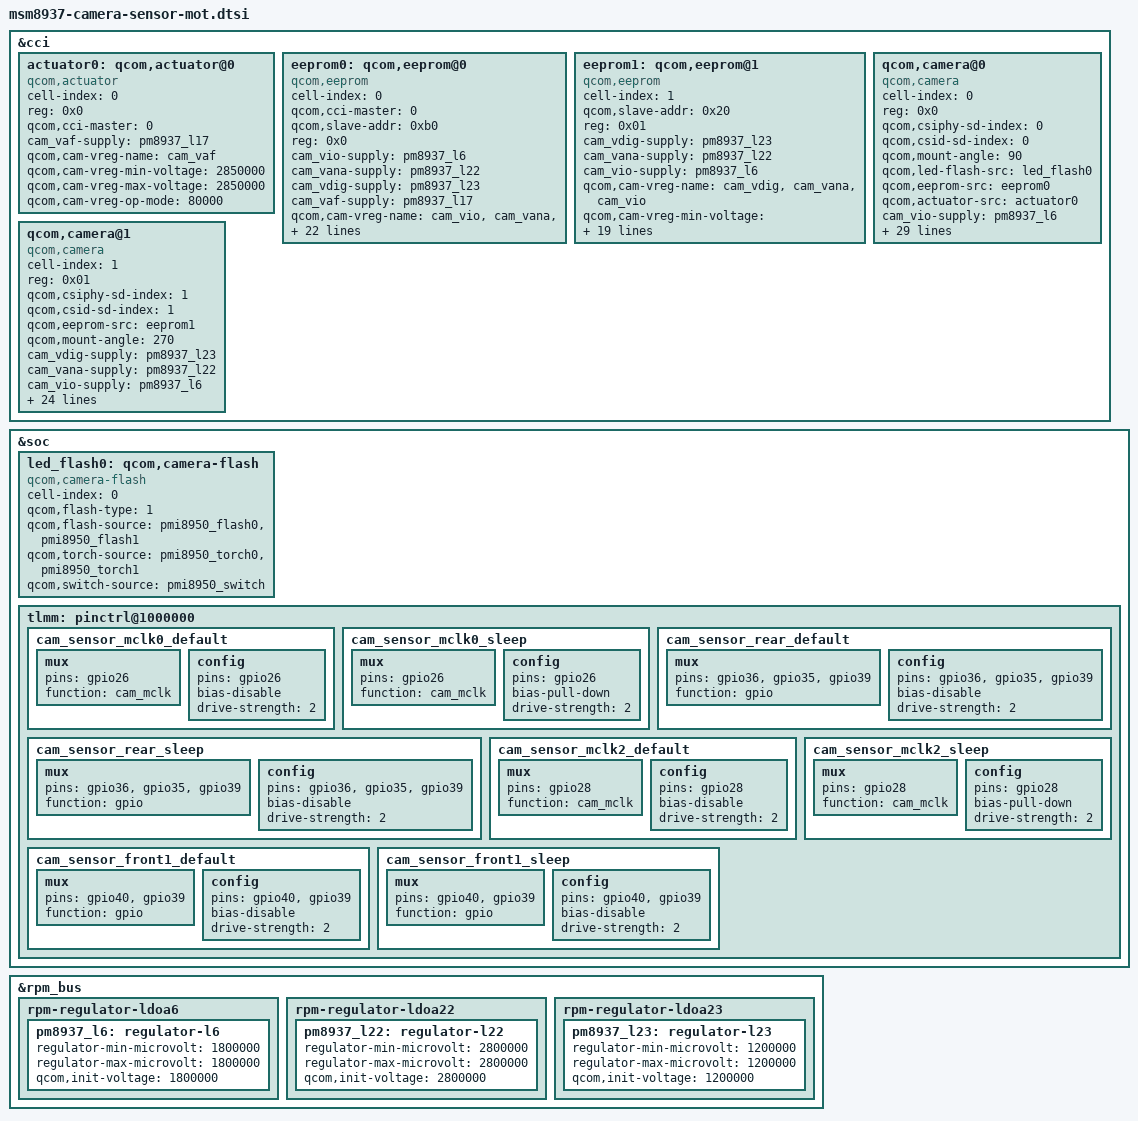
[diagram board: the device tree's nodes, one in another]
/*
 * Copyright (c) 2015-2016, The Linux Foundation. All rights reserved.
 *
 * This program is free software; you can redistribute it and/or modify
 * it under the terms of the GNU General Public License version 2 and
 * only version 2 as published by the Free Software Foundation.
 *
 * This program is distributed in the hope that it will be useful,
 * but WITHOUT ANY WARRANTY; without even the implied warranty of
 * MERCHANTABILITY or FITNESS FOR A PARTICULAR PURPOSE.  See the
 * GNU General Public License for more details.
 */

&cci {
	actuator0: qcom,actuator@0 {
		cell-index = <0>;
		reg = <0x0>;
		compatible = "qcom,actuator";
		qcom,cci-master = <0>;
		cam_vaf-supply = <&pm8937_l17>;
		qcom,cam-vreg-name = "cam_vaf";
		qcom,cam-vreg-min-voltage = <2850000>;
		qcom,cam-vreg-max-voltage = <2850000>;
		qcom,cam-vreg-op-mode = <80000>;
	};

	eeprom0: qcom,eeprom@0 {
		cell-index = <0>;
		compatible = "qcom,eeprom";
		qcom,cci-master = <0>;
		qcom,slave-addr = <0xb0>;
		reg = <0x0>;
		cam_vio-supply = <&pm8937_l6>;
		cam_vana-supply = <&pm8937_l22>;
		cam_vdig-supply = <&pm8937_l23>;
		cam_vaf-supply = <&pm8937_l17>;
		qcom,cam-vreg-name = "cam_vio","cam_vana","cam_vdig","cam_vaf";
		qcom,cam-vreg-min-voltage = <1800000 2800000 1200000 2850000>;
		qcom,cam-vreg-max-voltage = <1800000 2800000 1200000 2850000>;
		qcom,cam-vreg-op-mode = <80000 80000 80000 100000>;
		pinctrl-names = "cam_default", "cam_suspend";
		pinctrl-0 = <&cam_sensor_mclk0_default
				&cam_sensor_rear_default>;
		pinctrl-1 = <&cam_sensor_mclk0_sleep &cam_sensor_rear_sleep>;
		gpios = <&tlmm 26 0>,
			<&tlmm 36 0>,
			<&tlmm 35 0>,
			<&tlmm 39 0>;
		qcom,gpio-reset = <1>;
		qcom,gpio-standby = <2>;
		qcom,gpio-vana = <3>;
		qcom,gpio-req-tbl-num = <0 1 2 3>;
		qcom,gpio-req-tbl-flags = <1 0 0 0>;
		qcom,gpio-req-tbl-label = "CAMIF_MCLK0",
			"CAM_RESET0",
			"CAM_STANDBY0",
			"CAM_VANA0";
		status = "ok";
		clocks = <&clock_gcc clk_mclk0_clk_src>,
				<&clock_gcc clk_gcc_camss_mclk0_clk>;
		clock-names = "cam_src_clk", "cam_clk";
		qcom,clock-rates = <19200000 0>;
	};

	eeprom1: qcom,eeprom@1 {
		cell-index = <1>;
		qcom,slave-addr = <0x20>;
		compatible = "qcom,eeprom";
		reg = <0x01>;
		cam_vdig-supply = <&pm8937_l23>;
		cam_vana-supply = <&pm8937_l22>;
		cam_vio-supply = <&pm8937_l6>;
		qcom,cam-vreg-name = "cam_vdig", "cam_vana", "cam_vio";
		qcom,cam-vreg-min-voltage = <1200000 2800000 1800000>;
		qcom,cam-vreg-max-voltage = <1200000 2800000 1800000>;
		qcom,cam-vreg-op-mode = <100000 100000 100000>;
		pinctrl-names = "cam_default", "cam_suspend";
		pinctrl-0 = <&cam_sensor_mclk2_default
			&cam_sensor_front1_default>;
		pinctrl-1 = <&cam_sensor_mclk2_sleep
					&cam_sensor_front1_sleep>;
		gpios = <&tlmm 28 0>,
			<&tlmm 40 0>,
			<&tlmm 39 0>;
		qcom,gpio-reset = <1>;
		qcom,gpio-vana = <2>;
		qcom,gpio-req-tbl-num = <0 1 2>;
		qcom,gpio-req-tbl-flags = <1 0 0>;
		qcom,gpio-req-tbl-label = "CAMIF_MCLK2",
			"CAM_RESET2",
			"CAM_VANA2";
		qcom,cci-master = <0>;
		status = "ok";
		clocks = <&clock_gcc clk_mclk2_clk_src>,
			<&clock_gcc clk_gcc_camss_mclk2_clk>;
		clock-names = "cam_src_clk", "cam_clk";
		qcom,clock-rates = <19200000 0>;
	};

	qcom,camera@0 {
		cell-index = <0>;
		compatible = "qcom,camera";
		reg = <0x0>;
		qcom,csiphy-sd-index = <0>;
		qcom,csid-sd-index = <0>;
		qcom,mount-angle = <90>;
		qcom,led-flash-src = <&led_flash0>;
		qcom,eeprom-src = <&eeprom0>;
		qcom,actuator-src = <&actuator0>;
		cam_vio-supply = <&pm8937_l6>;
		cam_vana-supply = <&pm8937_l22>;
		cam_vdig-supply = <&pm8937_l23>;
		cam_vaf-supply = <&pm8937_l17>;
		qcom,cam-vreg-name = "cam_vio","cam_vana","cam_vdig","cam_vaf";
		qcom,cam-vreg-min-voltage = <1800000 2800000 1200000 2850000>;
		qcom,cam-vreg-max-voltage = <1800000 2800000 1200000 2850000>;
		qcom,cam-vreg-op-mode = <80000 80000 80000 100000>;
		pinctrl-names = "cam_default", "cam_suspend";
		pinctrl-0 = <&cam_sensor_mclk0_default
				&cam_sensor_rear_default>;
		pinctrl-1 = <&cam_sensor_mclk0_sleep &cam_sensor_rear_sleep>;
		gpios = <&tlmm 26 0>,
			<&tlmm 36 0>,
			<&tlmm 35 0>,
			<&tlmm 39 0>;
		qcom,gpio-reset = <1>;
		qcom,gpio-standby = <2>;
		qcom,gpio-vana = <3>;
		qcom,gpio-req-tbl-num = <0 1 2 3>;
		qcom,gpio-req-tbl-flags = <1 0 0 0>;
		qcom,gpio-req-tbl-label = "CAMIF_MCLK0",
			"CAM_RESET0",
			"CAM_STANDBY0",
			"CAM_VANA0";
		qcom,sensor-position = <0>;
		qcom,sensor-mode = <0>;
		qcom,cci-master = <0>;
		status = "ok";
		clocks = <&clock_gcc clk_mclk0_clk_src>,
				<&clock_gcc clk_gcc_camss_mclk0_clk>;
		clock-names = "cam_src_clk", "cam_clk";
		qcom,clock-rates = <24000000 0>;
	};

	qcom,camera@1 {
		cell-index = <1>;
		compatible = "qcom,camera";
		reg = <0x01>;
		qcom,csiphy-sd-index = <1>;
		qcom,csid-sd-index = <1>;
		qcom,eeprom-src = <&eeprom1>;
		qcom,mount-angle = <270>;
		cam_vdig-supply = <&pm8937_l23>;
		cam_vana-supply = <&pm8937_l22>;
		cam_vio-supply = <&pm8937_l6>;
		qcom,cam-vreg-name = "cam_vdig", "cam_vana", "cam_vio";
		qcom,cam-vreg-min-voltage = <1200000 2800000 1800000>;
		qcom,cam-vreg-max-voltage = <1200000 2800000 1800000>;
		qcom,cam-vreg-op-mode = <100000 100000 100000>;
		pinctrl-names = "cam_default", "cam_suspend";
		pinctrl-0 = <&cam_sensor_mclk2_default
				&cam_sensor_front1_default>;
		pinctrl-1 = <&cam_sensor_mclk2_sleep
				&cam_sensor_front1_sleep>;
		gpios = <&tlmm 28 0>,
			<&tlmm 40 0>,
			<&tlmm 39 0>;
		qcom,gpio-reset = <1>;
		qcom,gpio-vana = <2>;
		qcom,gpio-req-tbl-num = <0 1 2>;
		qcom,gpio-req-tbl-flags = <1 0 0>;
		qcom,gpio-req-tbl-label = "CAMIF_MCLK2",
			"CAM_RESET2",
			"CAM_VANA2";
		qcom,sensor-position = <1>;
		qcom,sensor-mode = <0>;
		qcom,cci-master = <0>;
		status = "ok";
		clocks = <&clock_gcc clk_mclk2_clk_src>,
				<&clock_gcc clk_gcc_camss_mclk2_clk>;
		clock-names = "cam_src_clk", "cam_clk";
		qcom,clock-rates = <24000000 0>;
	};
};

&soc {
	led_flash0: qcom,camera-flash {
		cell-index = <0>;
		compatible = "qcom,camera-flash";
		qcom,flash-type = <1>;
		qcom,flash-source = <&pmi8950_flash0 &pmi8950_flash1>;
		qcom,torch-source = <&pmi8950_torch0 &pmi8950_torch1>;
		qcom,switch-source = <&pmi8950_switch>;
	};
};

&soc {
	tlmm: pinctrl@1000000 {
		cam_sensor_mclk0_default: cam_sensor_mclk0_default {
			/* MCLK0 */
			mux {
				/* CLK, DATA */
				pins = "gpio26";
				function = "cam_mclk";
			};

			config {
				pins = "gpio26";
				bias-disable; /* No PULL */
				drive-strength = <2>; /* 2 MA */
			};
		};

		cam_sensor_mclk0_sleep: cam_sensor_mclk0_sleep {
			/* MCLK0 */
			mux {
				/* CLK, DATA */
				pins = "gpio26";
				function = "cam_mclk";
			};

			config {
				pins = "gpio26";
				bias-pull-down; /* PULL DOWN */
				drive-strength = <2>; /* 2 MA */
			};
		};

		cam_sensor_rear_default: cam_sensor_rear_default {
			/* RESET, STANDBY, VANA0 */
			mux {
				pins = "gpio36", "gpio35", "gpio39";
				function = "gpio";
			};

			config {
				pins = "gpio36","gpio35", "gpio39";
				bias-disable; /* No PULL */
				drive-strength = <2>; /* 2 MA */
			};
		};

		cam_sensor_rear_sleep: cam_sensor_rear_sleep {
			/* RESET, STANDBY, VANA0 */
			mux {
				pins = "gpio36","gpio35", "gpio39";
				function = "gpio";
			};

			config {
				pins = "gpio36","gpio35", "gpio39";
				bias-disable; /* No PULL */
				drive-strength = <2>; /* 2 MA */
			};
		};

		cam_sensor_mclk2_default: cam_sensor_mclk2_default {
			/* MCLK2 */
			mux {
				/* CLK, DATA */
				pins = "gpio28";
				function = "cam_mclk";
			};

			config {
				pins = "gpio28";
				bias-disable; /* No PULL */
				drive-strength = <2>; /* 2 MA */
			};
		};

		cam_sensor_mclk2_sleep: cam_sensor_mclk2_sleep {
			/* MCLK2 */
			mux {
				/* CLK, DATA */
				pins = "gpio28";
				function = "cam_mclk";
			};

			config {
				pins = "gpio28";
				bias-pull-down; /* PULL DOWN */
				drive-strength = <2>; /* 2 MA */
			};
		};

		cam_sensor_front1_default: cam_sensor_front1_default {
			/* RESET, VANA2 */
			mux {
				pins = "gpio40", "gpio39";
				function = "gpio";
			};

			config {
				pins = "gpio40", "gpio39";
				bias-disable; /* No PULL */
				drive-strength = <2>; /* 2 MA */
			};
		};

		cam_sensor_front1_sleep: cam_sensor_front1_sleep {
			/* RESET, VANA2 */
			mux {
				pins = "gpio40", "gpio39";
				function = "gpio";
			};

			config {
				pins = "gpio40", "gpio39";
				bias-disable; /* No PULL */
				drive-strength = <2>; /* 2 MA */
			};
		};
	};
};

&rpm_bus {
	rpm-regulator-ldoa6 {
		status = "okay";
		pm8937_l6: regulator-l6 {
			regulator-min-microvolt = <1800000>;
			regulator-max-microvolt = <1800000>;
			qcom,init-voltage = <1800000>;
			status = "okay";
		};
	};

	rpm-regulator-ldoa22 {
		status = "okay";
		pm8937_l22: regulator-l22 {
			regulator-min-microvolt = <2800000>;
			regulator-max-microvolt = <2800000>;
			qcom,init-voltage = <2800000>;
			status = "okay";
		};
	};

	rpm-regulator-ldoa23 {
		status = "okay";
		pm8937_l23: regulator-l23 {
			regulator-min-microvolt = <1200000>;
			regulator-max-microvolt = <1200000>;
			qcom,init-voltage = <1200000>;
			status = "okay";
		};
	};
};

